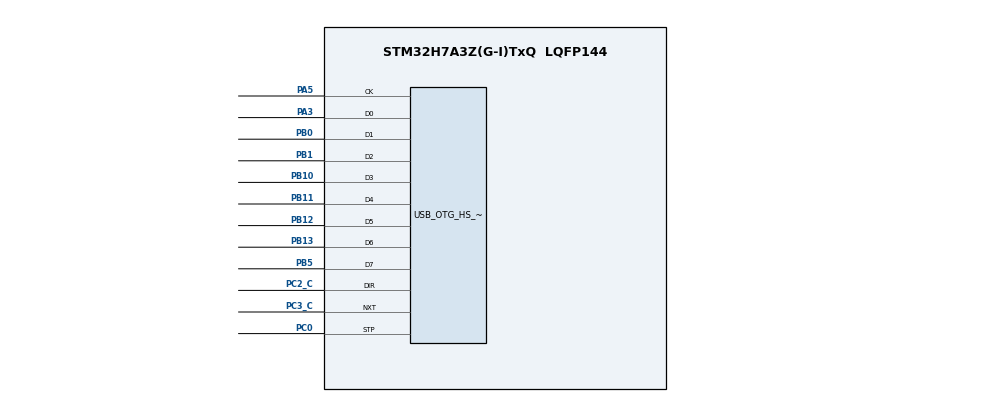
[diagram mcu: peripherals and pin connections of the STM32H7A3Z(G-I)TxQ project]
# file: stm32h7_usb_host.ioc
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Mcu.Family=STM32H7
Mcu.Name=STM32H7A3Z(G-I)TxQ
Mcu.Package=LQFP144
NVIC.PriorityGroup=NVIC_PRIORITYGROUP_4
PA3.Mode=Host_HS
PA3.Signal=USB_OTG_HS_ULPI_D0
PA5.Mode=Host_HS
PA5.Signal=USB_OTG_HS_ULPI_CK
PB0.Mode=Host_HS
PB0.Signal=USB_OTG_HS_ULPI_D1
PB1.Mode=Host_HS
PB1.Signal=USB_OTG_HS_ULPI_D2
PB10.Mode=Host_HS
PB10.Signal=USB_OTG_HS_ULPI_D3
PB11.Mode=Host_HS
PB11.Signal=USB_OTG_HS_ULPI_D4
PB12.Mode=Host_HS
PB12.Signal=USB_OTG_HS_ULPI_D5
PB13.Mode=Host_HS
PB13.Signal=USB_OTG_HS_ULPI_D6
PB5.Mode=Host_HS
PB5.Signal=USB_OTG_HS_ULPI_D7
PC0.Mode=Host_HS
PC0.Signal=USB_OTG_HS_ULPI_STP
PC2_C.Mode=Host_HS
PC2_C.Signal=USB_OTG_HS_ULPI_DIR
PC3_C.Mode=Host_HS
PC3_C.Signal=USB_OTG_HS_ULPI_NXT
ProjectManager.HeapSize=0x200
ProjectManager.StackSize=0x400
ProjectManager.TargetToolchain=MDK-ARM V5.32
RCC.ADCFreq_Value=129000000
RCC.APB1Freq_Value=64000000
RCC.APB2Freq_Value=64000000
RCC.APB3Freq_Value=64000000
RCC.APB4Freq_Value=64000000
RCC.CortexFreq_Value=64000000
RCC.HCLKFreq_Value=64000000
RCC.SYSCLKFreq_VALUE=64000000
RCC.USBCLockSelection=RCC_USBCLKSOURCE_HSI48
RCC.USBFreq_Value=48000000
USB_OTG_HS.VirtualMode-Host_HS=Host_HS
board=custom

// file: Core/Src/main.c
/* USER CODE BEGIN Header */
/**
  ******************************************************************************
  * @file           : main.c
  * @brief          : Main program body
  ******************************************************************************
  * @attention
  *
  * Copyright (c) 2023 STMicroelectronics.
  * All rights reserved.
  *
  * This software is licensed under terms that can be found in the LICENSE file
  * in the root directory of this software component.
  * If no LICENSE file comes with this software, it is provided AS-IS.
  *
  ******************************************************************************
  */
/* USER CODE END Header */
#include "main.h"
#include "usb_otg.h"
#include "gpio.h"
#include "EventRecorder.h"
#include "EventRecorderConf.h"

void SystemClock_Config(void);
static void MPU_Initialize(void);
static void MPU_Config(void);

int main(void)
{

  /* MCU Configuration--------------------------------------------------------*/

  /* Reset of all peripherals, Initializes the Flash interface and the Systick. */
  HAL_Init();

  /* MPU Configuration--------------------------------------------------------*/
  MPU_Config();

  /* Configure the system clock */
  SystemClock_Config();

  /* Initialize all configured peripherals */
  MX_GPIO_Init();
  MX_USB_OTG_HS_HCD_Init();
  /* USER CODE BEGIN 2 */

	EventRecorderInitialize(EventRecordAll, 1U);
	EventRecorderStart();

  /* USER CODE END 2 */

  /* Infinite loop */
  while (1)
  {

		printf("test 11\n");
		HAL_Delay(1000);
  }
}

void SystemClock_Config(void)
{
  RCC_OscInitTypeDef RCC_OscInitStruct = {0};
  RCC_ClkInitTypeDef RCC_ClkInitStruct = {0};

  /*AXI clock gating */
  RCC->CKGAENR = 0xFFFFFFFF;

  /** Supply configuration update enable
  */
  HAL_PWREx_ConfigSupply(PWR_DIRECT_SMPS_SUPPLY);

  /** Configure the main internal regulator output voltage
  */
  __HAL_PWR_VOLTAGESCALING_CONFIG(PWR_REGULATOR_VOLTAGE_SCALE3);

  while(!__HAL_PWR_GET_FLAG(PWR_FLAG_VOSRDY)) {}

  /** Initializes the RCC Oscillators according to the specified parameters
  * in the RCC_OscInitTypeDef structure.
  */
  RCC_OscInitStruct.OscillatorType = RCC_OSCILLATORTYPE_HSI48|RCC_OSCILLATORTYPE_HSI;
  RCC_OscInitStruct.HSIState = RCC_HSI_DIV1;
  RCC_OscInitStruct.HSICalibrationValue = 64;
  RCC_OscInitStruct.HSI48State = RCC_HSI48_ON;
  RCC_OscInitStruct.PLL.PLLState = RCC_PLL_NONE;
  if (HAL_RCC_OscConfig(&RCC_OscInitStruct) != HAL_OK)
  {
    Error_Handler();
  }

  /** Initializes the CPU, AHB and APB buses clocks
  */
  RCC_ClkInitStruct.ClockType = RCC_CLOCKTYPE_HCLK|RCC_CLOCKTYPE_SYSCLK
                              |RCC_CLOCKTYPE_PCLK1|RCC_CLOCKTYPE_PCLK2
                              |RCC_CLOCKTYPE_D3PCLK1|RCC_CLOCKTYPE_D1PCLK1;
  RCC_ClkInitStruct.SYSCLKSource = RCC_SYSCLKSOURCE_HSI;
  RCC_ClkInitStruct.SYSCLKDivider = RCC_SYSCLK_DIV1;
  RCC_ClkInitStruct.AHBCLKDivider = RCC_HCLK_DIV1;
  RCC_ClkInitStruct.APB3CLKDivider = RCC_APB3_DIV1;
  RCC_ClkInitStruct.APB1CLKDivider = RCC_APB1_DIV1;
  RCC_ClkInitStruct.APB2CLKDivider = RCC_APB2_DIV1;
  RCC_ClkInitStruct.APB4CLKDivider = RCC_APB4_DIV1;

  if (HAL_RCC_ClockConfig(&RCC_ClkInitStruct, FLASH_LATENCY_2) != HAL_OK)
  {
    Error_Handler();
  }
}

/* MPU Configuration */

void MPU_Config(void)
{
  MPU_Region_InitTypeDef MPU_InitStruct = {0};

  /* Disables the MPU */
  HAL_MPU_Disable();

  /** Initializes and configures the Region and the memory to be protected
  */
  MPU_InitStruct.Enable = MPU_REGION_ENABLE;
  MPU_InitStruct.Number = MPU_REGION_NUMBER0;
  MPU_InitStruct.BaseAddress = 0x0;
  MPU_InitStruct.Size = MPU_REGION_SIZE_4GB;
  MPU_InitStruct.SubRegionDisable = 0x87;
  MPU_InitStruct.TypeExtField = MPU_TEX_LEVEL0;
  MPU_InitStruct.AccessPermission = MPU_REGION_NO_ACCESS;
  MPU_InitStruct.DisableExec = MPU_INSTRUCTION_ACCESS_DISABLE;
  MPU_InitStruct.IsShareable = MPU_ACCESS_SHAREABLE;
  MPU_InitStruct.IsCacheable = MPU_ACCESS_NOT_CACHEABLE;
  MPU_InitStruct.IsBufferable = MPU_ACCESS_NOT_BUFFERABLE;

  HAL_MPU_ConfigRegion(&MPU_InitStruct);
  /* Enables the MPU */
  HAL_MPU_Enable(MPU_PRIVILEGED_DEFAULT);

}

void Error_Handler(void)
{
  __disable_irq();
  while (1)
  {
  }
}
